# AltaRiscv register map
File version: 1.0
Registers are 32-bit, read-write, reset 0x0 unless marked. A register's access mark holds for its fields unless they carry their own. Offsets are from the block's base; [hi:lo] are bit positions; {n}, {i} and the like mark numbered series.

## PLIC — Platform local interrupt controller
Base 0x0C000000
0x04 FLASH_PRIORITY — Acting priority of interrupt FLASH
  [3:0] FLASH_PRIORITY
0x08 RTC_PRIORITY — Acting priority of interrupt RTC
  [3:0] RTC_PRIORITY
0x0C FCB0_PRIORITY — Acting priority of interrupt FCB0
  [3:0] FCB0_PRIORITY
0x10 WATCHDOG0_PRIORITY — Acting priority of interrupt WATCHDOG0
  [3:0] WATCHDOG0_PRIORITY
0x14 SPI0_PRIORITY — Acting priority of interrupt SPI0
  [3:0] SPI0_PRIORITY
0x18 SPI1_PRIORITY — Acting priority of interrupt SPI1
  [3:0] SPI1_PRIORITY
{0x1C+4i} GPIO{i}_PRIORITY (i=0..9) — Acting priority of interrupt GPIO{i}
  [3:0] GPIO{i}_PRIORITY
0x44 TIMER0_PRIORITY — Acting priority of interrupt TIMER0
  [3:0] TIMER0_PRIORITY
0x48 TIMER1_PRIORITY — Acting priority of interrupt TIMER1
  [3:0] TIMER1_PRIORITY
{0x4C+4i} GPTIMER{i}_PRIORITY (i=0..4) — Acting priority of interrupt GPTIMER{i}
  [3:0] GPTIMER{i}_PRIORITY
{0x60+4i} UART{i}_PRIORITY (i=0..4) — Acting priority of interrupt UART{i}
  [3:0] UART{i}_PRIORITY
0x74 CAN0_PRIORITY — Acting priority of interrupt CAN0
  [3:0] CAN0_PRIORITY
0x78 I2C0_PRIORITY — Acting priority of interrupt I2C0
  [3:0] I2C0_PRIORITY
0x7C I2C1_PRIORITY — Acting priority of interrupt I2C1
  [3:0] I2C1_PRIORITY
0x80 DMAC0_INTR_PRIORITY — Acting priority of interrupt DMAC0_INTR
  [3:0] DMAC0_INTR_PRIORITY
0x84 DMAC0_INTTC_PRIORITY — Acting priority of interrupt DMAC0_INTTC
  [3:0] DMAC0_INTTC_PRIORITY
0x88 DMAC0_INTERR_PRIORITY — Acting priority of interrupt DMAC0_INTERR
  [3:0] DMAC0_INTERR_PRIORITY
0x8C USB0_PRIORITY — Acting priority of interrupt USB0
  [3:0] USB0_PRIORITY
0x90 MAC0_PRIORITY — Acting priority of interrupt MAC0
  [3:0] MAC0_PRIORITY
{0x94+4i} EXT_INT{i}_PRIORITY (i=0..7) — Acting priority of interrupt EXT_INT{i}
  [3:0] EXT_INT{i}_PRIORITY
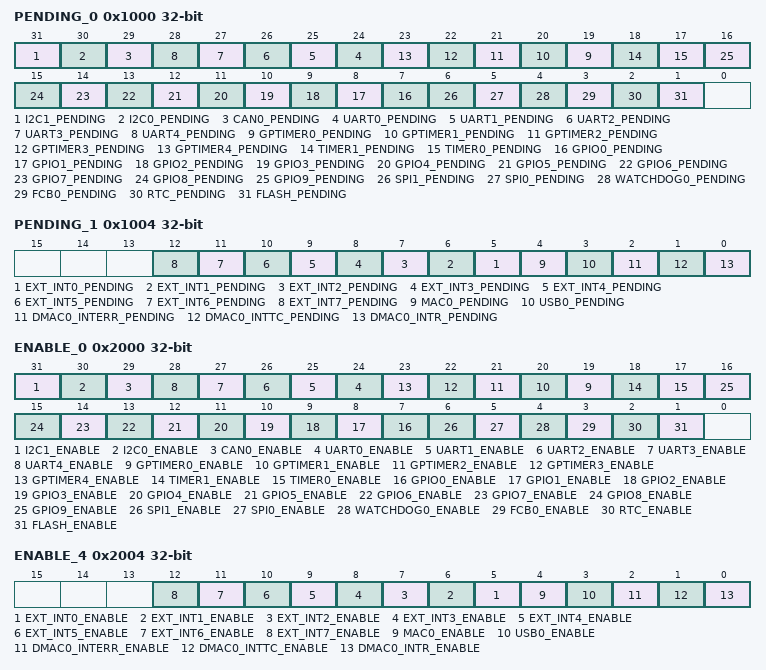
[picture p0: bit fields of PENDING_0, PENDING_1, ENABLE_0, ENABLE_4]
0x1000 PENDING_0 ro — Pending bit array
  [31] I2C1_PENDING — Pending bit for interrupt I2C1
  [30] I2C0_PENDING — Pending bit for interrupt I2C0
  [29] CAN0_PENDING — Pending bit for interrupt CAN0
  [n+24] UART{n}_PENDING (n=0..4) — Pending bit for interrupt UART{n}
  [n+19] GPTIMER{n}_PENDING (n=0..4) — Pending bit for interrupt GPTIMER{n}
  [18] TIMER1_PENDING — Pending bit for interrupt TIMER1
  [17] TIMER0_PENDING — Pending bit for interrupt TIMER0
  [n+7] GPIO{n}_PENDING (n=0..9) — Pending bit for interrupt GPIO{n}
  [6] SPI1_PENDING — Pending bit for interrupt SPI1
  [5] SPI0_PENDING — Pending bit for interrupt SPI0
  [4] WATCHDOG0_PENDING — Pending bit for interrupt WATCHDOG0
  [3] FCB0_PENDING — Pending bit for interrupt FCB0
  [2] RTC_PENDING — Pending bit for interrupt RTC
  [1] FLASH_PENDING — Pending bit for interrupt FLASH
0x1004 PENDING_1 ro — Pending bit array
  [n+5] EXT_INT{n}_PENDING (n=0..7) — Pending bit for interrupt EXT_INT{n}
  [4] MAC0_PENDING — Pending bit for interrupt MAC0
  [3] USB0_PENDING — Pending bit for interrupt USB0
  [2] DMAC0_INTERR_PENDING — Pending bit for interrupt DMAC0_INTERR
  [1] DMAC0_INTTC_PENDING — Pending bit for interrupt DMAC0_INTTC
  [0] DMAC0_INTR_PENDING — Pending bit for interrupt DMAC0_INTR
0x2000 ENABLE_0 — Enable bits for each interrupt source for target 0. 1 bit for each interrupt source.
  [31] I2C1_ENABLE — Enable bit for interrupt I2C1
  [30] I2C0_ENABLE — Enable bit for interrupt I2C0
  [29] CAN0_ENABLE — Enable bit for interrupt CAN0
  [n+24] UART{n}_ENABLE (n=0..4) — Enable bit for interrupt UART{n}
  [n+19] GPTIMER{n}_ENABLE (n=0..4) — Enable bit for interrupt GPTIMER{n}
  [18] TIMER1_ENABLE — Enable bit for interrupt TIMER1
  [17] TIMER0_ENABLE — Enable bit for interrupt TIMER0
  [n+7] GPIO{n}_ENABLE (n=0..9) — Enable bit for interrupt GPIO{n}
  [6] SPI1_ENABLE — Enable bit for interrupt SPI1
  [5] SPI0_ENABLE — Enable bit for interrupt SPI0
  [4] WATCHDOG0_ENABLE — Enable bit for interrupt WATCHDOG0
  [3] FCB0_ENABLE — Enable bit for interrupt FCB0
  [2] RTC_ENABLE — Enable bit for interrupt RTC
  [1] FLASH_ENABLE — Enable bit for interrupt FLASH
0x2004 ENABLE_4 — Enable bits for each interrupt source for target 0. 1 bit for each interrupt source.
  [n+5] EXT_INT{n}_ENABLE (n=0..7) — Enable bit for interrupt EXT_INT{n}
  [4] MAC0_ENABLE — Enable bit for interrupt MAC0
  [3] USB0_ENABLE — Enable bit for interrupt USB0
  [2] DMAC0_INTERR_ENABLE — Enable bit for interrupt DMAC0_INTERR
  [1] DMAC0_INTTC_ENABLE — Enable bit for interrupt DMAC0_INTTC
  [0] DMAC0_INTR_ENABLE — Enable bit for interrupt DMAC0_INTR
0x200000 THRESHOLD_0 — Interrupt claim threshold for target 0. Maximum value is 15.
  [3:0] THRESHOLD_0
0x200004 CLAIM_COMPLETE_0 — Claim/Complete register for Target 0. Reading this register returns the claimed interrupt number and makes it no longer pending.Writing the interrupt number back completes the interrupt.
